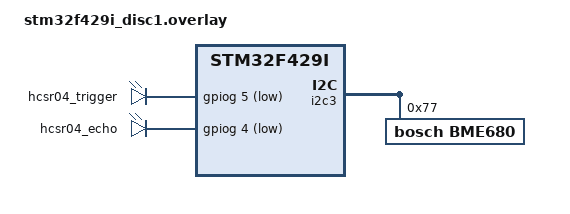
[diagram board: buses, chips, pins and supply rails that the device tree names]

/ {
    leds {
        // Add Trigger on PG5
        hcsr04_trigger: hcsr04_trig {
            gpios = <&gpiog 5 GPIO_ACTIVE_LOW>;
        };
        hcsr04_echo: hcsr04_ech {
			gpios = <&gpiog 4 GPIO_ACTIVE_LOW>;
        };
    };

    aliases {
        ultrasonictrigger = &hcsr04_trigger;
        ultrasonicecho = &hcsr04_echo;
    };

    chosen {
        perso,bme680 = &bme680;
    };
};

&i2c3 {
    bme680: bme680@77 {
        compatible = "bosch,bme680";
        reg = <0x77>;
        label = "BME680";
    };
};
